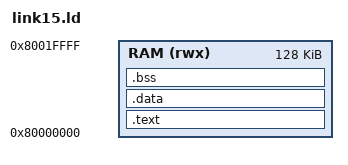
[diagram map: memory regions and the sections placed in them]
OUTPUT_ARCH(riscv)
ENTRY(_start)

MEMORY
{
  RAM (rwx) : ORIGIN = 0x80000000, LENGTH = 128K
}

SECTIONS
{
  .text : {
    *(.text*)
    *(.rodata*)
  } > RAM

  .data : {
    *(.data*)
  } > RAM

  .bss : {
    *(.bss*)
    *(COMMON)
  } > RAM
}
